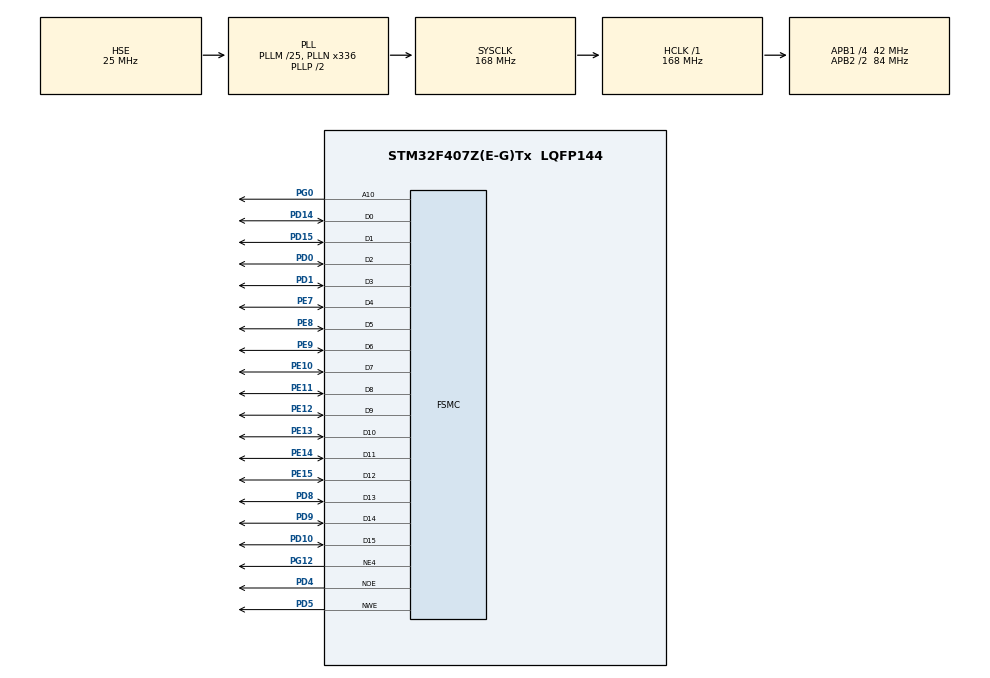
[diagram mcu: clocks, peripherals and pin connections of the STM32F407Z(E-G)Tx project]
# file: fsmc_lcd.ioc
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FSMC.AddressSetupTime1=6
FSMC.BusTurnAroundDuration1=0
FSMC.DataSetupTime1=6
Mcu.Family=STM32F4
Mcu.Name=STM32F407Z(E-G)Tx
Mcu.Package=LQFP144
NVIC.PriorityGroup=NVIC_PRIORITYGROUP_4
PC14-OSC32_IN.Mode=LSE-External-Oscillator
PC14-OSC32_IN.Signal=RCC_OSC32_IN
PC15-OSC32_OUT.Mode=LSE-External-Oscillator
PC15-OSC32_OUT.Signal=RCC_OSC32_OUT
PD0.Signal=FSMC_D2_DA2
PD1.Signal=FSMC_D3_DA3
PD10.Signal=FSMC_D15_DA15
PD14.Signal=FSMC_D0_DA0
PD15.Signal=FSMC_D1_DA1
PD4.Signal=FSMC_NOE
PD5.Signal=FSMC_NWE
PD8.Signal=FSMC_D13_DA13
PD9.Signal=FSMC_D14_DA14
PE10.Signal=FSMC_D7_DA7
PE11.Signal=FSMC_D8_DA8
PE12.Signal=FSMC_D9_DA9
PE13.Signal=FSMC_D10_DA10
PE14.Signal=FSMC_D11_DA11
PE15.Signal=FSMC_D12_DA12
PE7.Signal=FSMC_D4_DA4
PE8.Signal=FSMC_D5_DA5
PE9.Signal=FSMC_D6_DA6
PG0.Signal=FSMC_A10
PG12.Mode=NorPsramChipSelect4_1
PG12.Signal=FSMC_NE4
PH0-OSC_IN.Mode=HSE-External-Oscillator
PH0-OSC_IN.Signal=RCC_OSC_IN
PH1-OSC_OUT.Mode=HSE-External-Oscillator
PH1-OSC_OUT.Signal=RCC_OSC_OUT
ProjectManager.HeapSize=0x200
ProjectManager.StackSize=0x400
ProjectManager.TargetToolchain=MDK-ARM V5
RCC.48MHZClocksFreq_Value=84000000
RCC.AHBFreq_Value=168000000
RCC.APB1CLKDivider=RCC_HCLK_DIV4
RCC.APB1Freq_Value=42000000
RCC.APB1TimFreq_Value=84000000
RCC.APB2CLKDivider=RCC_HCLK_DIV2
RCC.APB2Freq_Value=84000000
RCC.APB2TimFreq_Value=168000000
RCC.CortexFreq_Value=168000000
RCC.HCLKFreq_Value=168000000
RCC.HSE_VALUE=25000000
RCC.HSI_VALUE=16000000
RCC.PLLM=25
RCC.PLLN=336
RCC.PLLSourceVirtual=RCC_PLLSOURCE_HSE
RCC.SYSCLKFreq_VALUE=168000000
RCC.SYSCLKSource=RCC_SYSCLKSOURCE_PLLCLK
RCC.VCOOutputFreq_Value=336000000
SH.FSMC_A10.0=FSMC_A10,A10_1
SH.FSMC_D0_DA0.0=FSMC_D0,16b-d1
SH.FSMC_D10_DA10.0=FSMC_D10,16b-d1
SH.FSMC_D11_DA11.0=FSMC_D11,16b-d1
SH.FSMC_D12_DA12.0=FSMC_D12,16b-d1
SH.FSMC_D13_DA13.0=FSMC_DA13
SH.FSMC_D13_DA13.1=FSMC_D13,16b-d1
SH.FSMC_D14_DA14.0=FSMC_D14,16b-d1
SH.FSMC_D15_DA15.0=FSMC_D15,16b-d1
SH.FSMC_D1_DA1.0=FSMC_D1,16b-d1
SH.FSMC_D2_DA2.0=FSMC_D2,16b-d1
SH.FSMC_D3_DA3.0=FSMC_D3,16b-d1
SH.FSMC_D4_DA4.0=FSMC_D4,16b-d1
SH.FSMC_D5_DA5.0=FSMC_D5,16b-d1
SH.FSMC_D6_DA6.0=FSMC_D6,16b-d1
SH.FSMC_D7_DA7.0=FSMC_D7,16b-d1
SH.FSMC_D8_DA8.0=FSMC_D8,16b-d1
SH.FSMC_D9_DA9.0=FSMC_D9,16b-d1
SH.FSMC_NOE.0=FSMC_NOE,Lcd1
SH.FSMC_NWE.0=FSMC_NWE,Lcd1
board=custom

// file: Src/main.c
/* USER CODE BEGIN Header */
/**
  ******************************************************************************
  * @file           : main.c
  * @brief          : Main program body
  ******************************************************************************
  * @attention
  *
  * <h2><center>&copy; Copyright (c) 2020 STMicroelectronics.
  * All rights reserved.</center></h2>
  *
  * This software component is licensed by ST under BSD 3-Clause license,
  * the "License"; You may not use this file except in compliance with the
  * License. You may obtain a copy of the License at:
  *                        opensource.org/licenses/BSD-3-Clause
  *
  ******************************************************************************
  */
/* USER CODE END Header */

#include "main.h"

/* USER CODE BEGIN Includes */
#include "ILI9486.h"
/* USER CODE END Includes */

SRAM_HandleTypeDef hsram1;

void SystemClock_Config(void);
static void MX_GPIO_Init(void);
static void MX_FSMC_Init(void);

int main(void)
{

  /* MCU Configuration--------------------------------------------------------*/

  /* Reset of all peripherals, Initializes the Flash interface and the Systick. */
  HAL_Init();

  /* Configure the system clock */
  SystemClock_Config();

  /* Initialize all configured peripherals */
  MX_GPIO_Init();
  MX_FSMC_Init();
  /* USER CODE BEGIN 2 */
	HAL_Delay(200);
	TFT_Init();
  /* USER CODE END 2 */

  /* Infinite loop */
  while (1)
  {

    /* USER CODE BEGIN 3 */
		HAL_Delay(200);
		TFT_DrawCircle(10,10,10, RED);
  }
  /* USER CODE END 3 */
}

void SystemClock_Config(void)
{
  RCC_OscInitTypeDef RCC_OscInitStruct = {0};
  RCC_ClkInitTypeDef RCC_ClkInitStruct = {0};

  /** Configure the main internal regulator output voltage
  */
  __HAL_RCC_PWR_CLK_ENABLE();
  __HAL_PWR_VOLTAGESCALING_CONFIG(PWR_REGULATOR_VOLTAGE_SCALE1);
  /** Initializes the CPU, AHB and APB busses clocks
  */
  RCC_OscInitStruct.OscillatorType = RCC_OSCILLATORTYPE_HSE;
  RCC_OscInitStruct.HSEState = RCC_HSE_ON;
  RCC_OscInitStruct.PLL.PLLState = RCC_PLL_ON;
  RCC_OscInitStruct.PLL.PLLSource = RCC_PLLSOURCE_HSE;
  RCC_OscInitStruct.PLL.PLLM = 25;
  RCC_OscInitStruct.PLL.PLLN = 336;
  RCC_OscInitStruct.PLL.PLLP = RCC_PLLP_DIV2;
  RCC_OscInitStruct.PLL.PLLQ = 4;
  if (HAL_RCC_OscConfig(&RCC_OscInitStruct) != HAL_OK)
  {
    Error_Handler();
  }
  /** Initializes the CPU, AHB and APB busses clocks
  */
  RCC_ClkInitStruct.ClockType = RCC_CLOCKTYPE_HCLK|RCC_CLOCKTYPE_SYSCLK
                              |RCC_CLOCKTYPE_PCLK1|RCC_CLOCKTYPE_PCLK2;
  RCC_ClkInitStruct.SYSCLKSource = RCC_SYSCLKSOURCE_PLLCLK;
  RCC_ClkInitStruct.AHBCLKDivider = RCC_SYSCLK_DIV1;
  RCC_ClkInitStruct.APB1CLKDivider = RCC_HCLK_DIV4;
  RCC_ClkInitStruct.APB2CLKDivider = RCC_HCLK_DIV2;

  if (HAL_RCC_ClockConfig(&RCC_ClkInitStruct, FLASH_LATENCY_5) != HAL_OK)
  {
    Error_Handler();
  }
}

static void MX_GPIO_Init(void)
{

  /* GPIO Ports Clock Enable */
  __HAL_RCC_GPIOC_CLK_ENABLE();
  __HAL_RCC_GPIOH_CLK_ENABLE();
  __HAL_RCC_GPIOG_CLK_ENABLE();
  __HAL_RCC_GPIOE_CLK_ENABLE();
  __HAL_RCC_GPIOD_CLK_ENABLE();

}

/* FSMC initialization function */
static void MX_FSMC_Init(void)
{

  FSMC_NORSRAM_TimingTypeDef Timing = {0};

  /** Perform the SRAM1 memory initialization sequence
  */
  hsram1.Instance = FSMC_NORSRAM_DEVICE;
  hsram1.Extended = FSMC_NORSRAM_EXTENDED_DEVICE;
  /* hsram1.Init */
  hsram1.Init.NSBank = FSMC_NORSRAM_BANK4;
  hsram1.Init.DataAddressMux = FSMC_DATA_ADDRESS_MUX_DISABLE;
  hsram1.Init.MemoryType = FSMC_MEMORY_TYPE_SRAM;
  hsram1.Init.MemoryDataWidth = FSMC_NORSRAM_MEM_BUS_WIDTH_16;
  hsram1.Init.BurstAccessMode = FSMC_BURST_ACCESS_MODE_DISABLE;
  hsram1.Init.WaitSignalPolarity = FSMC_WAIT_SIGNAL_POLARITY_LOW;
  hsram1.Init.WrapMode = FSMC_WRAP_MODE_DISABLE;
  hsram1.Init.WaitSignalActive = FSMC_WAIT_TIMING_BEFORE_WS;
  hsram1.Init.WriteOperation = FSMC_WRITE_OPERATION_ENABLE;
  hsram1.Init.WaitSignal = FSMC_WAIT_SIGNAL_DISABLE;
  hsram1.Init.ExtendedMode = FSMC_EXTENDED_MODE_DISABLE;
  hsram1.Init.AsynchronousWait = FSMC_ASYNCHRONOUS_WAIT_DISABLE;
  hsram1.Init.WriteBurst = FSMC_WRITE_BURST_DISABLE;
  hsram1.Init.PageSize = FSMC_PAGE_SIZE_NONE;
  /* Timing */
  Timing.AddressSetupTime = 6;
  Timing.AddressHoldTime = 15;
  Timing.DataSetupTime = 6;
  Timing.BusTurnAroundDuration = 0;
  Timing.CLKDivision = 16;
  Timing.DataLatency = 17;
  Timing.AccessMode = FSMC_ACCESS_MODE_A;
  /* ExtTiming */

  if (HAL_SRAM_Init(&hsram1, &Timing, NULL) != HAL_OK)
  {
    Error_Handler( );
  }

}

void Error_Handler(void)
{
}

/************************ (C) COPYRIGHT STMicroelectronics *****END OF FILE****/
